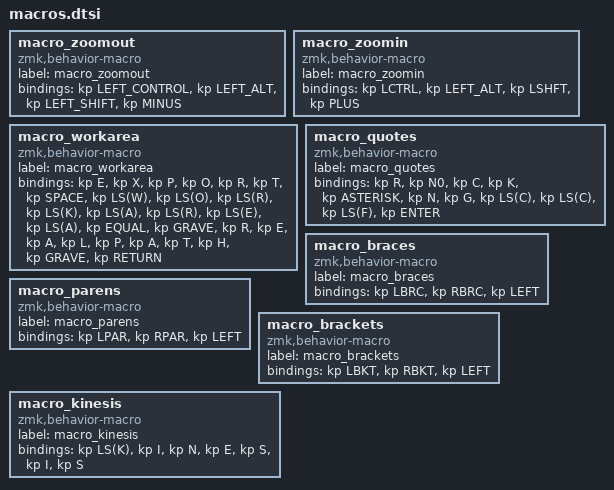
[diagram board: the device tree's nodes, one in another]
macro_zoomout: macro_zoomout{
compatible = "zmk,behavior-macro";
label = "macro_zoomout";
#binding-cells = <0>;
bindings = <&kp LEFT_CONTROL>, <&kp LEFT_ALT>, <&kp LEFT_SHIFT>, <&kp MINUS>;
};
macro_zoomin: macro_zoomin{
compatible = "zmk,behavior-macro";
label = "macro_zoomin";
#binding-cells = <0>;
bindings = <&kp LCTRL>, <&kp LEFT_ALT>, <&kp LSHFT>, <&kp PLUS>;
};
macro_workarea: macro_workarea{
compatible = "zmk,behavior-macro";
label = "macro_workarea";
#binding-cells = <0>;
bindings = <&kp E>, <&kp X>, <&kp P>, <&kp O>, <&kp R>, <&kp T>, <&kp SPACE>, <&kp LS(W)>, <&kp LS(O)>, <&kp LS(R)>, <&kp LS(K)>, <&kp LS(A)>, <&kp LS(R)>, <&kp LS(E)>, <&kp LS(A)>, <&kp EQUAL>, <&kp GRAVE>, <&kp R>, <&kp E>, <&kp A>, <&kp L>, <&kp P>, <&kp A>, <&kp T>, <&kp H>, <&kp GRAVE>, <&kp RETURN>;
};
macro_quotes: macro_quotes{
compatible = "zmk,behavior-macro";
label = "macro_quotes";
#binding-cells = <0>;
bindings = <&kp R>, <&kp N0>, <&kp C>, <&kp K>, <&kp ASTERISK>, <&kp N>, <&kp G>, <&kp LS(C)>, <&kp LS(C)>, <&kp LS(F)>, <&kp ENTER>;
};
macro_braces: macro_braces{
compatible = "zmk,behavior-macro";
label = "macro_braces";
#binding-cells = <0>;
bindings = <&kp LBRC>, <&kp RBRC>, <&kp LEFT>;
};
macro_parens: macro_parens{
compatible = "zmk,behavior-macro";
label = "macro_parens";
#binding-cells = <0>;
bindings = <&kp LPAR>, <&kp RPAR>, <&kp LEFT>;
};
macro_brackets: macro_brackets{
compatible = "zmk,behavior-macro";
label = "macro_brackets";
#binding-cells = <0>;
bindings = <&kp LBKT>, <&kp RBKT>, <&kp LEFT>;
};
macro_kinesis: macro_kinesis{
compatible = "zmk,behavior-macro";
label = "macro_kinesis";
#binding-cells = <0>;
bindings = <&kp LS(K)>, <&kp I>, <&kp N>, <&kp E>, <&kp S>, <&kp I>, <&kp S>;
};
